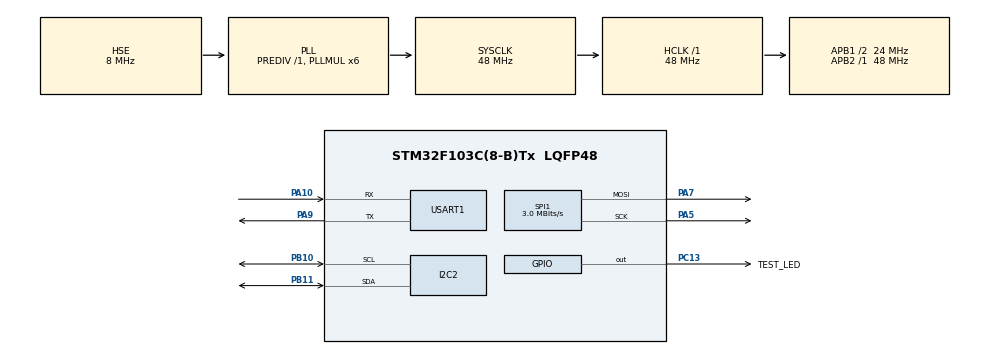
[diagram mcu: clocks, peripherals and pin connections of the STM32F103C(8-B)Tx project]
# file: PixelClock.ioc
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Dma.Request0=SPI1_TX
Dma.Request1=USART1_RX
Dma.Request2=USART1_TX
Dma.SPI1_TX.0.Direction=DMA_MEMORY_TO_PERIPH
Dma.SPI1_TX.0.Instance=DMA1_Channel3
Dma.SPI1_TX.0.MemDataAlignment=DMA_MDATAALIGN_BYTE
Dma.SPI1_TX.0.MemInc=DMA_MINC_ENABLE
Dma.SPI1_TX.0.Mode=DMA_NORMAL
Dma.SPI1_TX.0.PeriphDataAlignment=DMA_PDATAALIGN_BYTE
Dma.SPI1_TX.0.PeriphInc=DMA_PINC_DISABLE
Dma.SPI1_TX.0.Priority=DMA_PRIORITY_LOW
Dma.USART1_RX.1.Direction=DMA_PERIPH_TO_MEMORY
Dma.USART1_RX.1.Instance=DMA1_Channel5
Dma.USART1_RX.1.MemDataAlignment=DMA_MDATAALIGN_BYTE
Dma.USART1_RX.1.MemInc=DMA_MINC_ENABLE
Dma.USART1_RX.1.Mode=DMA_CIRCULAR
Dma.USART1_RX.1.PeriphDataAlignment=DMA_PDATAALIGN_BYTE
Dma.USART1_RX.1.PeriphInc=DMA_PINC_DISABLE
Dma.USART1_RX.1.Priority=DMA_PRIORITY_LOW
Dma.USART1_TX.2.Direction=DMA_MEMORY_TO_PERIPH
Dma.USART1_TX.2.Instance=DMA1_Channel4
Dma.USART1_TX.2.MemDataAlignment=DMA_MDATAALIGN_BYTE
Dma.USART1_TX.2.MemInc=DMA_MINC_ENABLE
Dma.USART1_TX.2.Mode=DMA_NORMAL
Dma.USART1_TX.2.PeriphDataAlignment=DMA_PDATAALIGN_BYTE
Dma.USART1_TX.2.PeriphInc=DMA_PINC_DISABLE
Dma.USART1_TX.2.Priority=DMA_PRIORITY_LOW
FREERTOS.INCLUDE_xEventGroupSetBitFromISR=1
FREERTOS.Tasks01=defaultTask,24,128,StartDefaultTask,Default,NULL,Dynamic,NULL,NULL;LedTask,8,128,StartLedTask,Default,NULL,Dynamic,NULL,NULL
I2C2.I2C_Mode=I2C_Standard
Mcu.Family=STM32F1
Mcu.Name=STM32F103C(8-B)Tx
Mcu.Package=LQFP48
NVIC.DMA1_Channel3_IRQn=true\:5\:0\:false\:false\:true\:true\:false\:true
NVIC.DMA1_Channel4_IRQn=true\:5\:0\:false\:false\:true\:true\:false\:true
NVIC.DMA1_Channel5_IRQn=true\:5\:0\:false\:false\:true\:true\:false\:true
NVIC.PriorityGroup=NVIC_PRIORITYGROUP_4
NVIC.RTC_IRQn=true\:5\:0\:false\:false\:true\:true\:true\:true
NVIC.TIM4_IRQn=true\:0\:0\:false\:false\:true\:false\:false\:true
NVIC.TimeBase=TIM4_IRQn
NVIC.TimeBaseIP=TIM4
NVIC.USART1_IRQn=true\:5\:0\:false\:false\:true\:true\:true\:true
PA10.Mode=Asynchronous
PA10.Signal=USART1_RX
PA13.Mode=Serial_Wire
PA13.Signal=SYS_JTMS-SWDIO
PA14.Mode=Serial_Wire
PA14.Signal=SYS_JTCK-SWCLK
PA5.Mode=TX_Only_Simplex_Unidirect_Master
PA5.Signal=SPI1_SCK
PA7.Mode=TX_Only_Simplex_Unidirect_Master
PA7.Signal=SPI1_MOSI
PA9.Mode=Asynchronous
PA9.Signal=USART1_TX
PB10.Mode=I2C
PB10.Signal=I2C2_SCL
PB11.Mode=I2C
PB11.Signal=I2C2_SDA
PC13-TAMPER-RTC.GPIO_Label=TEST_LED
PC13-TAMPER-RTC.Signal=GPIO_Output
PC14-OSC32_IN.Mode=LSE-External-Oscillator
PC14-OSC32_IN.Signal=RCC_OSC32_IN
PC15-OSC32_OUT.Mode=LSE-External-Oscillator
PC15-OSC32_OUT.Signal=RCC_OSC32_OUT
PD0-OSC_IN.Mode=HSE-External-Oscillator
PD0-OSC_IN.Signal=RCC_OSC_IN
PD1-OSC_OUT.Mode=HSE-External-Oscillator
PD1-OSC_OUT.Signal=RCC_OSC_OUT
ProjectManager.HeapSize=0x200
ProjectManager.StackSize=0x400
ProjectManager.TargetToolchain=STM32CubeIDE
RCC.AHBFreq_Value=48000000
RCC.APB1CLKDivider=RCC_HCLK_DIV2
RCC.APB1Freq_Value=24000000
RCC.APB1TimFreq_Value=48000000
RCC.APB2Freq_Value=48000000
RCC.APB2TimFreq_Value=48000000
RCC.HCLKFreq_Value=48000000
RCC.PLLMUL=RCC_PLL_MUL6
RCC.PLLSourceVirtual=RCC_PLLSOURCE_HSE
RCC.RTCClockSelection=RCC_RTCCLKSOURCE_LSE
RCC.SYSCLKFreq_VALUE=48000000
RCC.SYSCLKSource=RCC_SYSCLKSOURCE_PLLCLK
RCC.USBFreq_Value=48000000
RTC.Format=RTC_FORMAT_BIN
SPI1.BaudRatePrescaler=SPI_BAUDRATEPRESCALER_16
SPI1.CalculateBaudRate=3.0 MBits/s
SPI1.DataSize=SPI_DATASIZE_8BIT
SPI1.Direction=SPI_DIRECTION_2LINES
SPI1.Mode=SPI_MODE_MASTER
SPI1.VirtualType=VM_MASTER
USART1.VirtualMode=VM_ASYNC
VP_FREERTOS_VS_CMSIS_V2.Mode=CMSIS_V2
VP_RTC_VS_RTC_Activate.Mode=RTC_Enabled
VP_SYS_VS_tim4.Mode=TIM4
board=custom

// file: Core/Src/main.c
/* USER CODE BEGIN Header */
/**
  ******************************************************************************
  * @file           : main.c
  * @brief          : Main program body
  ******************************************************************************
  * @attention
  *
  * <h2><center>&copy; Copyright (c) 2020 STMicroelectronics.
  * All rights reserved.</center></h2>
  *
  * This software component is licensed by ST under BSD 3-Clause license,
  * the "License"; You may not use this file except in compliance with the
  * License. You may obtain a copy of the License at:
  *                        opensource.org/licenses/BSD-3-Clause
  *
  ******************************************************************************
  */
/* USER CODE END Header */

#include "main.h"
#include "cmsis_os.h"

/* USER CODE BEGIN Includes */
#include "math.h"
#include "stdlib.h"
#include "time.h"
#include "ds3231.h"
/* USER CODE END Includes */

/* USER CODE BEGIN PTD */
enum flag_frame_state {
	WAIT_FOR_FRAME_START,
	WAIT_FOR_DATA
};

typedef enum font_size {
	THREE_BY_FIVE,
	THREE_BY_SEVEN,
	FOUR_BY_SEVEN,
	FOUR_BY_EIGHT,
	FIVE_BY_SEVEN,
	FIVE_BY_EIGHT
} t_font_size;

/* USER CODE END PTD */

/* USER CODE BEGIN PD */
#define	OFFSET			1
#define	NUM_ROW			8
#define NUM_COLUMN		20

#define NUM_LEDS				((NUM_ROW * NUM_COLUMN) + OFFSET)
#define	PIXELS_DATA_SIZE		NUM_LEDS*3
#define TOTAL_PIXELS_DATA_SIZE 	PIXELS_DATA_SIZE*3 + 1 //+1 to keep mosi Low by default to simulate proper LED reset condition

#define RX_DATA_SIZE 128
#define TX_DATA_SIZE 128

/* USER CODE END PD */

/* USER CODE BEGIN PM */
#define ARRAY_LEN(x)            (sizeof(x) / sizeof((x)[0]))
/* USER CODE END PM */

I2C_HandleTypeDef hi2c2;

RTC_HandleTypeDef hrtc;

SPI_HandleTypeDef hspi1;
DMA_HandleTypeDef hdma_spi1_tx;

UART_HandleTypeDef huart1;
DMA_HandleTypeDef hdma_usart1_rx;
DMA_HandleTypeDef hdma_usart1_tx;

/* Definitions for defaultTask */
osThreadId_t defaultTaskHandle;
const osThreadAttr_t defaultTask_attributes = {
  .name = "defaultTask",
  .priority = (osPriority_t) osPriorityNormal,
  .stack_size = 128 * 4
};
/* Definitions for LedTask */
osThreadId_t LedTaskHandle;
const osThreadAttr_t LedTask_attributes = {
  .name = "LedTask",
  .priority = (osPriority_t) osPriorityLow,
  .stack_size = 128 * 4
};
/* USER CODE BEGIN PV */

static uint8_t uart_rx_data[RX_DATA_SIZE];
static uint8_t uart_tx_data[TX_DATA_SIZE];

uint8_t	leda[TOTAL_PIXELS_DATA_SIZE]; //display pixel
uint8_t	leda_foreground[TOTAL_PIXELS_DATA_SIZE]; //foreground color

volatile uint8_t r_offset_dig_0,r_offset_dig_1,r_offset_dig_2,r_offset_dig_3;

static const uint8_t encoderLookup[256*3]={	0x92,0x49,0x24,0x92,0x49,0x26,0x92,0x49,0x34,0x92,0x49,0x36,0x92,0x49,0xA4,0x92,0x49,0xA6,0x92,0x49,0xB4,0x92,0x49,0xB6,0x92,0x4D,0x24,0x92,0x4D,0x26,0x92,0x4D,0x34,0x92,0x4D,0x36,0x92,0x4D,0xA4,0x92,0x4D,0xA6,0x92,0x4D,0xB4,0x92,0x4D,0xB6,0x92,0x69,0x24,0x92,0x69,0x26,0x92,0x69,0x34,0x92,0x69,0x36,0x92,0x69,0xA4,0x92,0x69,0xA6,0x92,0x69,0xB4,0x92,0x69,0xB6,0x92,0x6D,0x24,0x92,0x6D,0x26,0x92,0x6D,0x34,0x92,0x6D,0x36,0x92,0x6D,0xA4,0x92,0x6D,0xA6,0x92,0x6D,0xB4,0x92,0x6D,0xB6,0x93,0x49,0x24,0x93,0x49,0x26,0x93,0x49,0x34,0x93,0x49,0x36,0x93,0x49,0xA4,0x93,0x49,0xA6,0x93,0x49,0xB4,0x93,0x49,0xB6,0x93,0x4D,0x24,0x93,0x4D,0x26,0x93,0x4D,0x34,0x93,0x4D,0x36,0x93,0x4D,0xA4,0x93,0x4D,0xA6,0x93,0x4D,0xB4,0x93,0x4D,0xB6,0x93,0x69,0x24,0x93,0x69,0x26,0x93,0x69,0x34,0x93,0x69,0x36,0x93,0x69,0xA4,0x93,0x69,0xA6,0x93,0x69,0xB4,0x93,0x69,0xB6,0x93,0x6D,0x24,0x93,0x6D,0x26,0x93,0x6D,0x34,0x93,0x6D,0x36,0x93,0x6D,0xA4,0x93,0x6D,0xA6,0x93,0x6D,0xB4,0x93,0x6D,0xB6,0x9A,0x49,0x24,0x9A,0x49,0x26,0x9A,0x49,0x34,0x9A,0x49,0x36,0x9A,0x49,0xA4,0x9A,0x49,0xA6,0x9A,0x49,0xB4,0x9A,0x49,0xB6,0x9A,0x4D,0x24,0x9A,0x4D,0x26,0x9A,0x4D,0x34,0x9A,0x4D,0x36,0x9A,0x4D,0xA4,0x9A,0x4D,0xA6,0x9A,0x4D,0xB4,0x9A,0x4D,0xB6,0x9A,0x69,0x24,0x9A,0x69,0x26,0x9A,0x69,0x34,0x9A,0x69,0x36,0x9A,0x69,0xA4,0x9A,0x69,\
											0xA6,0x9A,0x69,0xB4,0x9A,0x69,0xB6,0x9A,0x6D,0x24,0x9A,0x6D,0x26,0x9A,0x6D,0x34,0x9A,0x6D,0x36,0x9A,0x6D,0xA4,0x9A,0x6D,0xA6,0x9A,0x6D,0xB4,0x9A,0x6D,0xB6,0x9B,0x49,0x24,0x9B,0x49,0x26,0x9B,0x49,0x34,0x9B,0x49,0x36,0x9B,0x49,0xA4,0x9B,0x49,0xA6,0x9B,0x49,0xB4,0x9B,0x49,0xB6,0x9B,0x4D,0x24,0x9B,0x4D,0x26,0x9B,0x4D,0x34,0x9B,0x4D,0x36,0x9B,0x4D,0xA4,0x9B,0x4D,0xA6,0x9B,0x4D,0xB4,0x9B,0x4D,0xB6,0x9B,0x69,0x24,0x9B,0x69,0x26,0x9B,0x69,0x34,0x9B,0x69,0x36,0x9B,0x69,0xA4,0x9B,0x69,0xA6,0x9B,0x69,0xB4,0x9B,0x69,0xB6,0x9B,0x6D,0x24,0x9B,0x6D,0x26,0x9B,0x6D,0x34,0x9B,0x6D,0x36,0x9B,0x6D,0xA4,0x9B,0x6D,0xA6,0x9B,0x6D,0xB4,0x9B,0x6D,0xB6,0xD2,0x49,0x24,0xD2,0x49,0x26,0xD2,0x49,0x34,0xD2,0x49,0x36,0xD2,0x49,0xA4,0xD2,0x49,0xA6,0xD2,0x49,0xB4,0xD2,0x49,0xB6,0xD2,0x4D,0x24,0xD2,0x4D,0x26,0xD2,0x4D,0x34,0xD2,0x4D,0x36,0xD2,0x4D,0xA4,0xD2,0x4D,0xA6,0xD2,0x4D,0xB4,0xD2,0x4D,0xB6,0xD2,0x69,0x24,0xD2,0x69,0x26,0xD2,0x69,0x34,0xD2,0x69,0x36,0xD2,0x69,0xA4,0xD2,0x69,0xA6,0xD2,0x69,0xB4,0xD2,0x69,0xB6,0xD2,0x6D,0x24,0xD2,0x6D,0x26,0xD2,0x6D,0x34,0xD2,0x6D,0x36,0xD2,0x6D,0xA4,0xD2,0x6D,0xA6,0xD2,0x6D,0xB4,0xD2,0x6D,0xB6,0xD3,0x49,0x24,0xD3,0x49,0x26,0xD3,0x49,0x34,0xD3,0x49,0x36,0xD3,0x49,0xA4,0xD3,0x49,0xA6,0xD3,0x49,0xB4,0xD3,0x49,0xB6,0xD3,0x4D,0x24,0xD3,0x4D,0x26,0xD3,0x4D,0x34,0xD3,\
											0x4D,0x36,0xD3,0x4D,0xA4,0xD3,0x4D,0xA6,0xD3,0x4D,0xB4,0xD3,0x4D,0xB6,0xD3,0x69,0x24,0xD3,0x69,0x26,0xD3,0x69,0x34,0xD3,0x69,0x36,0xD3,0x69,0xA4,0xD3,0x69,0xA6,0xD3,0x69,0xB4,0xD3,0x69,0xB6,0xD3,0x6D,0x24,0xD3,0x6D,0x26,0xD3,0x6D,0x34,0xD3,0x6D,0x36,0xD3,0x6D,0xA4,0xD3,0x6D,0xA6,0xD3,0x6D,0xB4,0xD3,0x6D,0xB6,0xDA,0x49,0x24,0xDA,0x49,0x26,0xDA,0x49,0x34,0xDA,0x49,0x36,0xDA,0x49,0xA4,0xDA,0x49,0xA6,0xDA,0x49,0xB4,0xDA,0x49,0xB6,0xDA,0x4D,0x24,0xDA,0x4D,0x26,0xDA,0x4D,0x34,0xDA,0x4D,0x36,0xDA,0x4D,0xA4,0xDA,0x4D,0xA6,0xDA,0x4D,0xB4,0xDA,0x4D,0xB6,0xDA,0x69,0x24,0xDA,0x69,0x26,0xDA,0x69,0x34,0xDA,0x69,0x36,0xDA,0x69,0xA4,0xDA,0x69,0xA6,0xDA,0x69,0xB4,0xDA,0x69,0xB6,0xDA,0x6D,0x24,0xDA,0x6D,0x26,0xDA,0x6D,0x34,0xDA,0x6D,0x36,0xDA,0x6D,0xA4,0xDA,0x6D,0xA6,0xDA,0x6D,0xB4,0xDA,0x6D,0xB6,0xDB,0x49,0x24,0xDB,0x49,0x26,0xDB,0x49,0x34,0xDB,0x49,0x36,0xDB,0x49,0xA4,0xDB,0x49,0xA6,0xDB,0x49,0xB4,0xDB,0x49,0xB6,0xDB,0x4D,0x24,0xDB,0x4D,0x26,0xDB,0x4D,0x34,0xDB,0x4D,0x36,0xDB,0x4D,0xA4,0xDB,0x4D,0xA6,0xDB,0x4D,0xB4,0xDB,0x4D,0xB6,0xDB,0x69,0x24,0xDB,0x69,0x26,0xDB,0x69,0x34,0xDB,0x69,0x36,0xDB,0x69,0xA4,0xDB,0x69,0xA6,0xDB,0x69,0xB4,0xDB,0x69,0xB6,0xDB,0x6D,0x24,0xDB,0x6D,0x26,0xDB,0x6D,0x34,0xDB,0x6D,0x36,0xDB,0x6D,0xA4,0xDB,0x6D,0xA6,0xDB,0x6D,0xB4,0xDB,0x6D,0xB6};

const uint8_t charmap_three_by_five[][3] = {
		{
				0b00000000, //0x00
				0b00000000,
				0b00000000
		},
		{
				0b00000000, //0x01
				0b00000000,
				0b00000000
		},
		{
				0b00000000, //0x02
				0b00000000,
				0b00000000
		},
		{
				0b00000000, //0x03
				0b00000000,
				0b00000000
		},
		{
				0b00000000, //0x04
				0b00000000,
				0b00000000
		},
		{
				0b00000000, //0x05
				0b00000000,
				0b00000000
		},
		{
				0b00000000, //0x06
				0b00000000,
				0b00000000
		},
		{
				0b00000000, //0x07
				0b00000000,
				0b00000000
		},
		{
				0b00000000, //0x08
				0b00000000,
				0b00000000
		},
		{
				0b00000000, //0x09
				0b00000000,
				0b00000000
		},
		{
				0b00000000, //0x0a
				0b00000000,
				0b00000000
		},
		{
				0b00000000, //0x0b
				0b00000000,
				0b00000000
		},
		{
				0b00000000, //0x0c
				0b00000000,
				0b00000000
		},
		{
				0b00000000, //0x0d
				0b00000000,
				0b00000000
		},
		{
				0b00000000, //0x0e
				0b00000000,
				0b00000000
		},
		{
				0b00000000, //0x0f
				0b00000000,
				0b00000000
		},
		{
				0b00000000, //0x10
				0b00000000,
				0b00000000
		},
		{
				0b00000000, //0x11
				0b00000000,
				0b00000000
		},
		{
				0b00000000, //0x12
				0b00000000,
				0b00000000
		},
		{
				0b00000000, //0x13
				0b00000000,
				0b00000000
		},
		{
				0b00000000, //0x14
				0b00000000,
				0b00000000
		},
		{
				0b00000000, //0x15
				0b00000000,
				0b00000000
		},
		{
				0b00000000, //16
				0b00000000,
				0b00000000
		},
		{
				0b00000000, //17
				0b00000000,
				0b00000000
		},
		{
				0b00000000, //18
				0b00000000,
				0b00000000
		},
		{
				0b00000000, //19
				0b00000000,
				0b00000000
		},
		{
				0b00000000, //1a
				0b00000000,
				0b00000000
		},
		{
				0b00000000, //1b
				0b00000000,
				0b00000000
		},
		{
				0b00000000, //1c
				0b00000000,
				0b00000000
		},
		{
				0b00000000, //1d
				0b00000000,
				0b00000000
		},
		{
				0b00000000, //1e
				0b00000000,
				0b00000000
		},
		{
				0b00000000, //1f
				0b00000000,
				0b00000000
		},
		{
				0b00000000, //20
				0b00000000,
				0b00000000
		},
		{
				0b00000000, //21 !
				0b00000000,
				0b00000000
		},
		{
				0b00000000, //22 "
				0b00000000,
				0b00000000
		},
		{
				0b00000000, //23 #
				0b00000000,
				0b00000000
		},
		{
				0b00000000, //24 $
				0b00000000,
				0b00000000
		},
		{
				0b00000000, //25 %
				0b00000000,
				0b00000000
		},
		{
				0b00000000, //26 &
				0b00000000,
				0b00000000
		},
		{
				0b00000000, //27 '
				0b00000000,
				0b00000000
		},
		{
				0b00000000, //28 (
				0b00000000,
				0b00000000
		},
		{
				0b00000000, //29 )
				0b00000000,
				0b00000000
		},
		{
				0b00000000, //2a *
				0b00000000,
				0b00000000
		},
		{
				0b00000000, //2b +
				0b00000000,
				0b00000000
		},
		{
				0b00000000, //2c ,
				0b00000000,
				0b00000000
		},
		{
				0b00000000, //2d -
				0b00000000,
				0b00000000
		},
		{
				0b00000000, //2e .
				0b00000000,
				0b00000000
		},
		{
				0b00000000, //2f /
				0b00000000,
				0b00000000
		},
		{
				0b00111110, //30 0
				0b01000001,
				0b00111110
		},
		{
				0b01000010, //31 1
				0b01111111,
				0b01000000
		},
		{
				0b01100010, //32 2
				0b01010001,
				0b01001110
		},
		{
				0b01001001, //33 3
				0b01001001,
				0b00110110
		},
		{
				0b00001111, //34 4
				0b00001000,
				0b01111100
		},
		{
				0b00100111, //35 5
				0b01000101,
				0b00111001
		},
		{
				0b00111110, //36 6
				0b01001001,
				0b00110010
		},
		{
				0b00000001, //37 7
				0b01111001,
				0b00000111
		},
		{
				0b00110110, //38 8
				0b01001001,
				0b00110110
		},
		{
				0b00100110, //39 9
				0b01001001,
				0b00111110
		},
		{
				0b00000000, //3a :
				0b00000000,
				0b00000000
		},
		{
				0b00000000, //3b ;
				0b00000000,
				0b00000000
		},
		{
				0b00001000, //3c <
				0b00010100,
				0b00100010
		},
		{
				0b00010100, //3d =
				0b00010100,
				0b00010100
		},
		{
				0b00100010, //3e >
				0b00010100,
				0b00001000
		},
		{
				0b00000010, //3f ?
				0b01011001,
				0b00000110
		},
		{
				0b00000000, //40 @
				0b00000000,
				0b00000000
		},
		{
				0b01111110, //41 A
				0b00010001,
				0b01111110
		},
		{
				0b01111111, //42 B
				0b01001001,
				0b00110110
		},
		{
				0b00111110, //43 C
				0b01000001,
				0b00100010
		},
		{
				0b01111111, //44 D
				0b01000001,
				0b00111110
		},
		{
				0b01111111, //45 E
				0b01001001,
				0b01000001
		},
		{
				0b01111111, //46 F
				0b00001001,
				0b00000001
		},
		{
				0b00111110, //47 G
				0b01000001,
				0b00110010
		},
		{
				0b01111111, //48 H
				0b00001000,
				0b01111111
		},
		{
				0b01000001, //49 I
				0b01111111,
				0b01000001
		},
		{
				0b00100000, //4a J
				0b01000001,
				0b00111111
		},
		{
				0b01111111, //4b K
				0b00010100,
				0b01000001
		},
		{
				0b01111111, //4c L
				0b01000000,
				0b01000000
		},
		{
				0b01111111, //4d M
				0b00000110,
				0b01111111
		},
		{
				0b01111111, //4e N
				0b00110000,
				0b01111111
		},
		{
				0b00111110, //4f O
				0b01000001,
				0b00111110
		},
		{
				0b01111111, //51 P
				0b00001001,
				0b00000110
		},
		{
				0b00111110, //52 Q
				0b01000001,
				0b01111110
		},
		{
				0b01111111, // R
				0b00011001,
				0b01100110
		},
		{
				0b00100110, // S
				0b01001001,
				0b00110010
		},
		{
				0b00000001, // T
				0b01111111,
				0b00000001
		},
		{
				0b00111111, // U
				0b01000000,
				0b00111111
		},
		{
				0b00011111, // V
				0b01000000,
				0b00011111
		},
		{
				0b01111111, // W
				0b00110000,
				0b01111111
		},
		{
				0b01100011, // X
				0b00011100,
				0b01100011
		},
		{
				0b00000111, // Y
				0b01111000,
				0b00000111
		},
		{
				0b01100001, // Z
				0b01011001,
				0b01000011
		},
		{
				0b01111111, // [
				0b01000001,
				0b00000000
		},
		{
				0b00000000, //
				0b00000000,
				0b00000000
		},
		{
				0b00000000, // ]
				0b01000001,
				0b01111111
		},
		{
				0b00000110, // ^
				0b00000001,
				0b00000110
		},
		{
				0b01000000, // _
				0b01000000,
				0b01000000
		},
		{
				0b00000001, // ~
				0b00000010,
				0b00000001
		},
		{
				0b00000000, // a
				0b00000000,
				0b00000000
		},
		{
				0b00000000, // b
				0b00000000,
				0b00000000
		}
};

const uint8_t charmap_three_by_seven[][3] = {
		{
				0b00000000, //0x00
				0b00000000,
				0b00000000
		},
		{
				0b00000000, //0x01
				0b00000000,
				0b00000000
		},
		{
				0b00000000, //0x02
				0b00000000,
				0b00000000
		},
		{
				0b00000000, //0x03
				0b00000000,
				0b00000000
		},
		{
				0b00000000, //0x04
				0b00000000,
				0b00000000
		},
		{
				0b00000000, //0x05
				0b00000000,
				0b00000000
		},
		{
				0b00000000, //0x06
				0b00000000,
				0b00000000
		},
		{
				0b00000000, //0x07
				0b00000000,
				0b00000000
		},
		{
				0b00000000, //0x08
				0b00000000,
				0b00000000
		},
		{
				0b00000000, //0x09
				0b00000000,
				0b00000000
		},
		{
				0b00000000, //0x0a
				0b00000000,
				0b00000000
		},
		{
				0b00000000, //0x0b
				0b00000000,
				0b00000000
		},
		{
				0b00000000, //0x0c
				0b00000000,
				0b00000000
		},
		{
				0b00000000, //0x0d
				0b00000000,
				0b00000000
		},
		{
				0b00000000, //0x0e
				0b00000000,
				0b00000000
		},
		{
				0b00000000, //0x0f
				0b00000000,
				0b00000000
		},
		{
				0b00000000, //0x10
				0b00000000,
				0b00000000
		},
		{
				0b00000000, //0x11
				0b00000000,
				0b00000000
		},
		{
				0b00000000, //0x12
				0b00000000,
				0b00000000
		},
		{
				0b00000000, //0x13
				0b00000000,
				0b00000000
		},
		{
				0b00000000, //0x14
				0b00000000,
				0b00000000
		},
		{
				0b00000000, //0x15
				0b00000000,
				0b00000000
		},
		{
				0b00000000, //16
				0b00000000,
				0b00000000
		},
		{
				0b00000000, //17
				0b00000000,
				0b00000000
		},
		{
				0b00000000, //18
				0b00000000,
				0b00000000
		},
		{
				0b00000000, //19
				0b00000000,
				0b00000000
		},
		{
				0b00000000, //1a
				0b00000000,
				0b00000000
		},
		{
				0b00000000, //1b
				0b00000000,
				0b00000000
		},
		{
				0b00000000, //1c
				0b00000000,
				0b00000000
		},
		{
				0b00000000, //1d
				0b00000000,
				0b00000000
		},
		{
				0b00000000, //1e
				0b00000000,
				0b00000000
		},
		{
				0b00000000, //1f
				0b00000000,
				0b00000000
		},
		{
				0b00000000, //20
				0b00000000,
				0b00000000
		},
		{
				0b00000000, //21 !
				0b00000000,
				0b00000000
		},
		{
				0b00000000, //22 "
				0b00000000,
				0b00000000
		},
		{
				0b00000000, //23 #
				0b00000000,
				0b00000000
		},
		{
				0b00000000, //24 $
				0b00000000,
				0b00000000
		},
		{
				0b00000000, //25 %
				0b00000000,
				0b00000000
		},
		{
				0b00000000, //26 &
				0b00000000,
				0b00000000
		},
		{
				0b00000000, //27 '
				0b00000000,
				0b00000000
		},
		{
				0b00000000, //28 (
				0b00000000,
				0b00000000
		},
		{
				0b00000000, //29 )
				0b00000000,
				0b00000000
		},
		{
				0b00000000, //2a *
				0b00000000,
				0b00000000
		},
		{
				0b00000000, //2b +
				0b00000000,
				0b00000000
		},
		{
				0b00000000, //2c ,
				0b00000000,
				0b00000000
		},
		{
				0b00000000, //2d -
				0b00000000,
				0b00000000
		},
		{
				0b00000000, //2e .
				0b00000000,
				0b00000000
		},
		{
				0b00000000, //2f /
				0b00000000,
				0b00000000
		},
		{
				0b00111110, //30 0
				0b01000001,
				0b00111110
		},
		{
				0b01000010, //31 1
				0b01111111,
				0b01000000
		},
		{
				0b01100010, //32 2
				0b01010001,
				0b01001110
		},
		{
				0b01001001, //33 3
				0b01001001,
				0b00110110
		},
		{
				0b00001111, //34 4
				0b00001000,
				0b01111100
		},
		{
				0b00100111, //35 5
				0b01000101,
				0b00111001
		},
		{
				0b00111110, //36 6
				0b01001001,
				0b00110010
		},
		{
				0b00000001, //37 7
				0b01111001,
				0b00000111
		},
		{
				0b00110110, //38 8
				0b01001001,
				0b00110110
		},
		{
				0b00100110, //39 9
				0b01001001,
				0b00111110
		},
		{
				0b00000000, //3a :
				0b00000000,
				0b00000000
		},
		{
				0b00000000, //3b ;
				0b00000000,
				0b00000000
		},
		{
				0b00001000, //3c <
				0b00010100,
				0b00100010
		},
		{
				0b00010100, //3d =
				0b00010100,
				0b00010100
		},
		{
				0b00100010, //3e >
				0b00010100,
				0b00001000
		},
		{
				0b00000010, //3f ?
				0b01011001,
				0b00000110
		},
		{
				0b00000000, //40 @
				0b00000000,
				0b00000000
		},
		{
				0b01111110, //41 A
				0b00010001,
				0b01111110
		},
		{
				0b01111111, //42 B
				0b01001001,
				0b00110110
		},
		{
				0b00111110, //43 C
				0b01000001,
				0b00100010
		},
		{
				0b01111111, //44 D
				0b01000001,
				0b00111110
		},
		{
				0b01111111, //45 E
				0b01001001,
				0b01000001
		},
		{
				0b01111111, //46 F
				0b00001001,
				0b00000001
		},
		{
				0b00111110, //47 G
				0b01000001,
				0b00110010
		},
		{
				0b01111111, //48 H
				0b00001000,
				0b01111111
		},
		{
				0b01000001, //49 I
				0b01111111,
				0b01000001
		},
		{
				0b00100000, //4a J
				0b01000001,
				0b00111111
		},
		{
				0b01111111, //4b K
				0b00010100,
				0b01000001
		},
		{
				0b01111111, //4c L
				0b01000000,
				0b01000000
		},
		{
				0b01111111, //4d M
				0b00000110,
				0b01111111
		},
		{
				0b01111111, //4e N
				0b00110000,
				0b01111111
		},
		{
				0b00111110, //4f O
				0b01000001,
				0b00111110
		},
		{
				0b01111111, //51 P
				0b00001001,
				0b00000110
		},
		{
				0b00111110, //52 Q
				0b01000001,
				0b01111110
		},
		{
				0b01111111, // R
				0b00011001,
				0b01100110
		},
		{
				0b00100110, // S
				0b01001001,
				0b00110010
		},
		{
				0b00000001, // T
				0b01111111,
				0b00000001
		},
		{
				0b00111111, // U
				0b01000000,
				0b00111111
		},
		{
				0b00011111, // V
				0b01000000,
				0b00011111
		},
		{
				0b01111111, // W
				0b00110000,
				0b01111111
		},
		{
				0b01100011, // X
				0b00011100,
				0b01100011
		},
		{
				0b00000111, // Y
				0b01111000,
				0b00000111
		},
		{
				0b01100001, // Z
				0b01011001,
				0b01000011
		},
		{
				0b01111111, // [
				0b01000001,
				0b00000000
		},
		{
				0b00000000, //
				0b00000000,
				0b00000000
		},
		{
				0b00000000, // ]
				0b01000001,
				0b01111111
		},
		{
				0b00000110, // ^
				0b00000001,
				0b00000110
		},
		{
				0b01000000, // _
				0b01000000,
				0b01000000
		},
		{
				0b00000001, // ~
				0b00000010,
				0b00000001
		},
		{
				0b00000000, // a
				0b00000000,
				0b00000000
		},
		{
				0b00000000, // b
				0b00000000,
				0b00000000
		}
};

const uint8_t charmap_four_by_seven[][4] = {
		{
				0b00000000, //0x00
				0b00000000,
				0b00000000,
				0b00000000
		},
		{
				0b00000000, //0x01
				0b00000000,
				0b00000000,
				0b00000000
		},
		{
				0b00000000, //0x02
				0b00000000,
				0b00000000,
				0b00000000
		},
		{
				0b00000000, //0x03
				0b00000000,
				0b00000000,
				0b00000000
		},
		{
				0b00000000, //0x04
				0b00000000,
				0b00000000,
				0b00000000
		},
		{
				0b00000000, //0x05
				0b00000000,
				0b00000000,
				0b00000000
		},
		{
				0b00000000, //0x06
				0b00000000,
				0b00000000,
				0b00000000
		},
		{
				0b00000000, //0x07
				0b00000000,
				0b00000000,
				0b00000000
		},
		{
				0b00000000, //0x08
				0b00000000,
				0b00000000,
				0b00000000
		},
		{
				0b00000000, //0x09
				0b00000000,
				0b00000000,
				0b00000000
		},
		{
				0b00000000, //0x0a
				0b00000000,
				0b00000000,
				0b00000000
		},
		{
				0b00000000, //0x0b
				0b00000000,
				0b00000000,
				0b00000000
		},
		{
				0b00000000, //0x0c
				0b00000000,
				0b00000000,
				0b00000000
		},
		{
				0b00000000, //0x0d
				0b00000000,
				0b00000000,
				0b00000000
		},
		{
				0b00000000, //0x0e
				0b00000000,
				0b00000000,
				0b00000000
		},
		{
				0b00000000, //0x0f
				0b00000000,
				0b00000000
		},
		{
				0b00000000, //0x10
				0b00000000,
				0b00000000,
				0b00000000
		},
		{
				0b00000000, //0x11
				0b00000000,
				0b00000000,
				0b00000000
		},
		{
				0b00000000, //0x12
				0b00000000,
				0b00000000,
				0b00000000
		},
		{
				0b00000000, //0x13
				0b00000000,
				0b00000000,
				0b00000000
		},
		{
				0b00000000, //0x14
				0b00000000,
				0b00000000,
				0b00000000
		},
		{
				0b00000000, //0x15
				0b00000000,
				0b00000000,
				0b00000000
		},
		{
				0b00000000, //16
				0b00000000,
				0b00000000,
				0b00000000
		},
		{
				0b00000000, //17
				0b00000000,
				0b00000000,
				0b00000000
		},
		{
				0b00000000, //18
				0b00000000,
				0b00000000,
				0b00000000
		},
		{
				0b00000000, //19
				0b00000000,
				0b00000000,
				0b00000000
		},
		{
				0b00000000, //1a
				0b00000000,
				0b00000000,
				0b00000000
		},
		{
				0b00000000, //1b
				0b00000000,
				0b00000000,
				0b00000000
		},
		{
				0b00000000, //1c
				0b00000000,
				0b00000000,
				0b00000000
		},
		{
				0b00000000, //1d
				0b00000000,
				0b00000000,
				0b00000000
		},
		{
				0b00000000, //1e
				0b00000000,
				0b00000000,
				0b00000000
		},
		{
				0b00000000, //1f
				0b00000000,
				0b00000000,
				0b00000000
		},
		{
				0b00000000, //20
				0b00000000,
				0b00000000,
				0b00000000
		},
		{
				0b00000000, //21 !
				0b00000000,
				0b00000000,
				0b00000000
		},
		{
				0b00000000, //22 "
				0b00000000,
				0b00000000,
				0b00000000
		},
		{
				0b00000000, //23 #
				0b00000000,
				0b00000000,
				0b00000000
		},
		{
				0b00000000, //24 $
				0b00000000,
				0b00000000,
				0b00000000
		},
		{
				0b00000000, //25 %
				0b00000000,
				0b00000000,
				0b00000000
		},
		{
				0b00000000, //26 &
				0b00000000,
				0b00000000,
				0b00000000
		},
		{
				0b00000000, //27 '
				0b00000000,
				0b00000000,
				0b00000000
		},
		{
				0b00000000, //28 (
				0b00000000,
				0b00000000,
				0b00000000
		},
		{
				0b00000000, //29 )
				0b00000000,
				0b00000000,
				0b00000000
		},
		{
				0b00000000, //2a *
				0b00000000,
				0b00000000,
				0b00000000
		},
		{
				0b00000000, //2b +
				0b00000000,
				0b00000000,
				0b00000000
		},
		{
				0b00000000, //2c ,
				0b00000000,
				0b00000000,
				0b00000000
		},
		{
				0b00000000, //2d -
				0b00000000,
				0b00000000,
				0b00000000
		},
		{
				0b00000000, //2e .
				0b00000000,
				0b00000000,
				0b00000000
		},
		{
				0b00000000, //2f /
				0b00000000,
				0b00000000,
				0b00000000
		},
		{
				0b00111110, //0
				0b01000001,
				0b01000001,
				0b00111110
		},
		{
				0b01000010, //1
				0b01111111,
				0b01000000,
				0b00000000
		},
		{
				0b01100010, //2
				0b01010001,
				0b01001001,
				0b01000110
		},
		{
				0b01001001, //3
				0b01001001,
				0b01001001,
				0b00110110
		},
		{
				0b00011111, //4
				0b00010000,
				0b01111100,
				0b00010000
		},
		{
				0b00100111, //5
				0b01000101,
				0b01000101,
				0b00111001
		},
		{
				0b00111110, //6
				0b01001001,
				0b01001001,
				0b00110000
		},
		{
				0b01100001, //7
				0b00010001,
				0b00001001,
				0b00000111
		},
		{
				0b00110110, //8
				0b01001001,
				0b01001001,
				0b00110110
		},
		{
				0b00000110, //9
				0b01001001,
				0b01001001,
				0b00111110
		},
		{
				0b00000000, //3a :
				0b00000000,
				0b00000000,
				0b00000000
		},
		{
				0b00000000, //3b ;
				0b00000000,
				0b00000000,
				0b00000000
		},
		{
				0b00001000, //3c <
				0b00010100,
				0b00000000,
				0b00100010
		},
		{
				0b00010100, //3d =
				0b00010100,
				0b00000000,
				0b00010100
		},
		{
				0b00100010, //3e >
				0b00010100,
				0b00000000,
				0b00001000
		},
		{
				0b00000010, //3f ?
				0b01011001,
				0b00000000,
				0b00000110
		},
		{
				0b00000000, //40 @
				0b00000000,
				0b00000000,
				0b00000000
		},
		{
				0b01111110, //41 A
				0b00010001,
				0b00000000,
				0b01111110
		},
		{
				0b01111111, //42 B
				0b01001001,
				0b00000000,
				0b00110110
		},
		{
				0b00111110, //43 C
				0b01000001,
				0b00000000,
				0b00100010
		},
		{
				0b01111111, //44 D
				0b01000001,
				0b00000000,
				0b00111110
		},
		{
				0b01111111, //45 E
				0b01001001,
				0b00000000,
				0b01000001
		},
		{
				0b01111111, //46 F
				0b00001001,
				0b00000000,
				0b00000001
		},
		{
				0b00111110, //47 G
				0b01000001,
				0b00000000,
				0b00110010
		},
		{
				0b01111111, //48 H
				0b00001000,
				0b00000000,
				0b01111111
		},
		{
				0b01000001, //49 I
				0b01111111,
				0b00000000,
				0b01000001
		},
		{
				0b00100000, //4a J
				0b01000001,
				0b00000000,
				0b00111111
		},
		{
				0b01111111, //4b K
				0b00010100,
				0b00000000,
				0b01000001
		},
		{
				0b01111111, //4c L
				0b01000000,
				0b00000000,
				0b01000000
		},
		{
				0b01111111, //4d M
				0b00000110,
				0b00000000,
				0b01111111
		},
		{
				0b01111111, //4e N
				0b00110000,
				0b00000000,
				0b01111111
		},
		{
				0b00111110, //4f O
				0b01000001,
				0b00000000,
				0b00111110
		},
		{
				0b01111111, //51 P
				0b00001001,
				0b00000000,
				0b00000110
		},
		{
				0b00111110, //52 Q
				0b01000001,
				0b00000000,
				0b01111110
		},
		{
				0b01111111, // R
				0b00011001,
				0b00000000,
				0b01100110
		},
		{
				0b00100110, // S
				0b01001001,
				0b00000000,
				0b00110010
		},
		{
				0b00000001, // T
				0b01111111,
				0b00000000,
				0b00000001
		},
		{
				0b00111111, // U
				0b01000000,
				0b00000000,
				0b00111111
		},
		{
				0b00011111, // V
				0b01000000,
				0b00000000,
				0b00011111
		},
		{
				0b01111111, // W
				0b00110000,
				0b00000000,
				0b01111111
		},
		{
				0b01100011, // X
				0b00011100,
				0b00000000,
				0b01100011
		},
		{
				0b00000111, // Y
				0b01111000,
				0b00000000,
				0b00000111
		},
		{
				0b01100001, // Z
				0b01011001,
				0b00000000,
				0b01000011
		},
		{
				0b01111111, // [
				0b01000001,
				0b00000000,
				0b00000000
		},
		{
				0b00000000, //
				0b00000000,
				0b00000000,
				0b00000000
		},
		{
				0b00000000, // ]
				0b01000001,
				0b00000000,
				0b01111111
		},
		{
				0b00000110, // ^
				0b00000001,
				0b00000000,
				0b00000110
		},
		{
				0b01000000, // _
				0b01000000,
				0b01000000
		},
		{
				0b00000001, // ~
				0b00000010,
				0b00000000,
				0b00000001
		},
		{
				0b00000000, // a
				0b00000000,
				0b00000000,
				0b00000000
		},
		{
				0b00000000, // b
				0b00000000,
				0b00000000,
				0b00000000
		}

};

const uint8_t charmap_five_by_seven[][5] = {
		{
				0b00000000, //0x00
				0b00000000,
				0b00000000,
				0b00000000,
				0b00000000
		},
		{
				0b00000000, //0x01
				0b00000000,
				0b00000000,
				0b00000000,
				0b00000000
		},
		{
				0b00000000, //0x02
				0b00000000,
				0b00000000,
				0b00000000,
				0b00000000
		},
		{
				0b00000000, //0x03
				0b00000000,
				0b00000000,
				0b00000000,
				0b00000000
		},
		{
				0b00000000, //0x04
				0b00000000,
				0b00000000,
				0b00000000,
				0b00000000
		},
		{
				0b00000000, //0x05
				0b00000000,
				0b00000000,
				0b00000000,
				0b00000000
		},
		{
				0b00000000, //0x06
				0b00000000,
				0b00000000,
				0b00000000,
				0b00000000
		},
		{
				0b00000000, //0x07
				0b00000000,
				0b00000000,
				0b00000000,
				0b00000000
		},
		{
				0b00000000, //0x08
				0b00000000,
				0b00000000,
				0b00000000,
				0b00000000
		},
		{
				0b00000000, //0x09
				0b00000000,
				0b00000000,
				0b00000000,
				0b00000000
		},
		{
				0b00000000, //0x0a
				0b00000000,
				0b00000000,
				0b00000000,
				0b00000000
		},
		{
				0b00000000, //0x0b
				0b00000000,
				0b00000000,
				0b00000000,
				0b00000000
		},
		{
				0b00000000, //0x0c
				0b00000000,
				0b00000000,
				0b00000000,
				0b00000000
		},
		{
				0b00000000, //0x0d
				0b00000000,
				0b00000000,
				0b00000000,
				0b00000000
		},
		{
				0b00000000, //0x0e
				0b00000000,
				0b00000000,
				0b00000000,
				0b00000000
		},
		{
				0b00000000, //0x0f
				0b00000000,
				0b00000000,
				0b00000000,
				0b00000000
		},
		{
				0b00000000, //0x10
				0b00000000,
				0b00000000,
				0b00000000,
				0b00000000
		},
		{
				0b00000000, //0x11
				0b00000000,
				0b00000000,
				0b00000000,
				0b00000000
		},
		{
				0b00000000, //0x12
				0b00000000,
				0b00000000,
				0b00000000,
				0b00000000
		},
		{
				0b00000000, //0x13
				0b00000000,
				0b00000000,
				0b00000000,
				0b00000000
		},
		{
				0b00000000, //0x14
				0b00000000,
				0b00000000,
				0b00000000,
				0b00000000
		},
		{
				0b00000000, //0x15
				0b00000000,
				0b00000000,
				0b00000000,
				0b00000000
		},
		{
				0b00000000, //16
				0b00000000,
				0b00000000,
				0b00000000,
				0b00000000
		},
		{
				0b00000000, //17
				0b00000000,
				0b00000000,
				0b00000000,
				0b00000000
		},
		{
				0b00000000, //18
				0b00000000,
				0b00000000,
				0b00000000,
				0b00000000
		},
		{
				0b00000000, //19
				0b00000000,
				0b00000000,
				0b00000000,
				0b00000000
		},
		{
				0b00000000, //1a
				0b00000000,
				0b00000000,
				0b00000000,
				0b00000000
		},
		{
				0b00000000, //1b
				0b00000000,
				0b00000000,
				0b00000000,
				0b00000000
		},
		{
				0b00000000, //1c
				0b00000000,
				0b00000000,
				0b00000000,
				0b00000000
		},
		{
				0b00000000, //1d
				0b00000000,
				0b00000000,
				0b00000000
		},
		{
				0b00000000, //1e
				0b00000000,
				0b00000000,
				0b00000000,
				0b00000000
		},
		{
				0b00000000, //1f
				0b00000000,
				0b00000000,
				0b00000000,
				0b00000000
		},
		{
				0b00000000, //20
				0b00000000,
				0b00000000,
				0b00000000,
				0b00000000
		},
		{
				0b00000000, //21 !
				0b00000000,
				0b00000000,
				0b00000000,
				0b00000000
		},
		{
				0b00000000, //22 "
				0b00000000,
				0b00000000,
				0b00000000,
				0b00000000
		},
		{
				0b00000000, //23 #
				0b00000000,
				0b00000000,
				0b00000000
		},
		{
				0b00000000, //24 $
				0b00000000,
				0b00000000,
				0b00000000,
				0b00000000
		},
		{
				0b00000000, //25 %
				0b00000000,
				0b00000000,
				0b00000000,
				0b00000000
		},
		{
				0b00000000, //26 &
				0b00000000,
				0b00000000,
				0b00000000,
				0b00000000
		},
		{
				0b00000000, //27 '
				0b00000000,
				0b00000000,
				0b00000000,
				0b00000000
		},
		{
				0b00000000, //28 (
				0b00000000,
				0b00000000,
				0b00000000,
				0b00000000
		},
		{
				0b00000000, //29 )
				0b00000000,
				0b00000000,
				0b00000000,
				0b00000000
		},
		{
				0b00000000, //2a *
				0b00000000,
				0b00000000,
				0b00000000,
				0b00000000
		},
		{
				0b00000000, //2b +
				0b00000000,
				0b00000000,
				0b00000000,
				0b00000000
		},
		{
				0b00000000, //2c ,
				0b00000000,
				0b00000000,
				0b00000000,
				0b00000000
		},
		{
				0b00000000, //2d -
				0b00000000,
				0b00000000,
				0b00000000,
				0b00000000
		},
		{
				0b00000000, //2e .
				0b00000000,
				0b00000000,
				0b00000000,
				0b00000000
		},
		{
				0b00000000, //2f /
				0b00000000,
				0b00000000,
				0b00000000,
				0b00000000
		},
		{
				0b00111110, //0
				0b01000001,
				0b01000001,
				0b00000000,
				0b00111110
		},
		{
				0b01000010, //1
				0b01111111,
				0b01000000,
				0b00000000,
				0b00000000
		},
		{
				0b01100010, //2
				0b01010001,
				0b01001001,
				0b00000000,
				0b01000110
		},
		{
				0b01001001, //3
				0b01001001,
				0b01001001,
				0b00000000,
				0b00110110
		},
		{
				0b00011111, //4
				0b00010000,
				0b01111100,
				0b00000000,
				0b00010000
		},
		{
				0b00100111, //5
				0b01000101,
				0b01000101,
				0b00000000,
				0b00111001
		},
		{
				0b00111110, //6
				0b01001001,
				0b01001001,
				0b00000000,
				0b00110000
		},
		{
				0b01100001, //7
				0b00010001,
				0b00001001,
				0b00000000,
				0b00000111
		},
		{
				0b00110110, //8
				0b01001001,
				0b01001001,
				0b00000000,
				0b00110110
		},
		{
				0b00000110, //9
				0b01001001,
				0b01001001,
				0b00000000,
				0b00111110
		},
		{
				0b00000000, //3a :
				0b00000000,
				0b00000000,
				0b00000000,
				0b00000000
		},
		{
				0b00000000, //3b ;
				0b00000000,
				0b00000000,
				0b00000000,
				0b00000000
		},
		{
				0b00001000, //3c <
				0b00010100,
				0b00000000,
				0b00000000,
				0b00100010
		},
		{
				0b00010100, //3d =
				0b00010100,
				0b00000000,
				0b00000000,
				0b00010100
		},
		{
				0b00100010, //3e >
				0b00010100,
				0b00000000,
				0b00000000,
				0b00001000
		},
		{
				0b00000010, //3f ?
				0b01011001,
				0b00000000,
				0b00000000,
				0b00000110
		},
		{
				0b00000000, //40 @
				0b00000000,
				0b00000000,
				0b00000000,
				0b00000000
		},
		{
				0b01111110, //41 A
				0b00010001,
				0b00000000,
				0b00000000,
				0b01111110
		},
		{
				0b01111111, //42 B
				0b01001001,
				0b00000000,
				0b00000000,
				0b00110110
		},
		{
				0b00111110, //43 C
				0b01000001,
				0b00000000,
				0b00000000,
				0b00100010
		},
		{
				0b01111111, //44 D
				0b01000001,
				0b00000000,
				0b00000000,
				0b00111110
		},
		{
				0b01111111, //45 E
				0b01001001,
				0b00000000,
				0b00000000,
				0b01000001
		},
		{
				0b01111111, //46 F
				0b00001001,
				0b00000000,
				0b00000000,
				0b00000001
		},
		{
				0b00111110, //47 G
				0b01000001,
				0b00000000,
				0b00000000,
				0b00110010
		},
		{
				0b01111111, //48 H
				0b00001000,
				0b00000000,
				0b00000000,
				0b01111111
		},
		{
				0b01000001, //49 I
				0b01111111,
				0b00000000,
				0b00000000,
				0b01000001
		},
		{
				0b00100000, //4a J
				0b01000001,
				0b00000000,
				0b00000000,
				0b00111111
		},
		{
				0b01111111, //4b K
				0b00010100,
				0b00000000,
				0b00000000,
				0b01000001
		},
		{
				0b01111111, //4c L
				0b01000000,
				0b00000000,
				0b00000000,
				0b01000000
		},
		{
				0b01111111, //4d M
				0b00000110,
				0b00000000,
				0b00000000,
				0b01111111
		},
		{
				0b01111111, //4e N
				0b00110000,
				0b00000000,
				0b00000000,
				0b01111111
		},
		{
				0b00111110, //4f O
				0b01000001,
				0b00000000,
				0b00000000,
				0b00111110
		},
		{
				0b01111111, //51 P
				0b00001001,
				0b00000000,
				0b00000000,
				0b00000110
		},
		{
				0b00111110, //52 Q
				0b01000001,
				0b00000000,
				0b00000000,
				0b01111110
		},
		{
				0b01111111, // R
				0b00011001,
				0b00000000,
				0b00000000,
				0b01100110
		},
		{
				0b00100110, // S
				0b01001001,
				0b00000000,
				0b00000000,
				0b00110010
		},
		{
				0b00000001, // T
				0b01111111,
				0b00000000,
				0b00000000,
				0b00000001
		},
		{
				0b00111111, // U
				0b01000000,
				0b00000000,
				0b00000000,
				0b00111111
		},
		{
				0b00011111, // V
				0b01000000,
				0b00000000,
				0b00000000,
				0b00011111
		},
		{
				0b01111111, // W
				0b00110000,
				0b00000000,
				0b00000000,
				0b01111111
		},
		{
				0b01100011, // X
				0b00011100,
				0b00000000,
				0b00000000,
				0b01100011
		},
		{
				0b00000111, // Y
				0b01111000,
				0b00000000,
				0b00000000,
				0b00000111
		},
		{
				0b01100001, // Z
				0b01011001,
				0b00000000,
				0b00000000,
				0b01000011
		},
		{
				0b01111111, // [
				0b01000001,
				0b00000000,
				0b00000000,
				0b00000000
		},
		{
				0b00000000, //
				0b00000000,
				0b00000000,
				0b00000000,
				0b00000000
		},
		{
				0b00000000, // ]
				0b01000001,
				0b00000000,
				0b00000000,
				0b01111111
		},
		{
				0b00000110, // ^
				0b00000001,
				0b00000000,
				0b00000000,
				0b00000110
		},
		{
				0b01000000, // _
				0b01000000,
				0b00000000,
				0b00000000,
				0b01000000
		},
		{
				0b00000001, // ~
				0b00000010,
				0b00000000,
				0b00000000,
				0b00000001
		},
		{
				0b00000000, // a
				0b00000000,
				0b00000000,
				0b00000000,
				0b00000000
		},
		{
				0b00000000, // b
				0b00000000,
				0b00000000,
				0b00000000,
				0b00000000
		}

};
uint32_t current_position;
uint8_t	flag_colon_display;

RTC_TimeTypeDef cTime;

osEventFlagsId_t uart1Event;
/* USER CODE END PV */

void SystemClock_Config(void);
static void MX_GPIO_Init(void);
static void MX_DMA_Init(void);
static void MX_RTC_Init(void);
static void MX_SPI1_Init(void);
static void MX_USART1_UART_Init(void);
static void MX_I2C2_Init(void);
void StartDefaultTask(void *argument);
void StartLedTask(void *argument);

/* USER CODE BEGIN PFP */
void handle_rx(UART_HandleTypeDef *huart);
void usart_process_data(const void* data, size_t len);
void setPixel(int Pixel, uint8_t red, uint8_t green, uint8_t blue);
void setPixel_foreground(int Pixel, uint8_t red, uint8_t green, uint8_t blue);
void setAll(uint8_t red, uint8_t green, uint8_t blue);
void setAll_foreground(uint8_t red, uint8_t green, uint8_t blue);
void copyForegroundPixel(int Pixel);
void showStrip(void);
void RGBLoop(void);
void RGBLoop_foreground(void);
void FadeInOut(uint8_t red, uint8_t green, uint8_t blue);
void rainbowCycle(void);
void rainbowCycle_foreground(void);
uint8_t * Wheel(uint8_t WheelPos);
void home(void);
void putchar_m(uint8_t c, t_font_size f_size, uint8_t *getColor(uint8_t arg));
void putchar_fg(uint8_t c, t_font_size f_size);
void putchar_fg_a(uint8_t prev_c, uint8_t c, t_font_size f_size,uint8_t row_offset);
void putcolon(void);
/* USER CODE END PFP */

/* USER CODE BEGIN 0 */
void HAL_RTCEx_RTCEventCallback(RTC_HandleTypeDef *hrtc){
	if(flag_colon_display) {
		flag_colon_display = 0;
	} else {
		flag_colon_display = 1;
	}
}

void HAL_UART_RxCpltCallback (UART_HandleTypeDef *huart){

	if(huart->Instance == USART1){ // WiFi
		handle_rx(huart);
		//osEventFlagsSet(uart1Event,0x01);
	}
}

void HAL_UART_ErrorCallback(UART_HandleTypeDef *huart )
{
	__HAL_UART_CLEAR_OREFLAG(huart);
	__HAL_UART_CLEAR_NEFLAG(huart);
	__HAL_UART_CLEAR_FEFLAG(huart);

	if(huart->Instance == USART1){
		HAL_UART_Receive_DMA(huart,uart_rx_data, RX_DATA_SIZE);
	}

}

void handle_rx(UART_HandleTypeDef *huart){
	static size_t old_pos;
	size_t pos;

	/* Calculate current position in buffer */
	pos = ARRAY_LEN(uart_rx_data) - huart->hdmarx->Instance->CNDTR;
	if (pos != old_pos) {
		if (pos > old_pos) {                    /* Current position is over previous one */
			/* We are in "linear" mode */
			/* Process data directly by subtracting "pointers" */
			usart_process_data(&uart_rx_data[old_pos], pos - old_pos);
		} else {
			/* We are in "overflow" mode */
			/* First process data to the end of buffer */
			usart_process_data(&uart_rx_data[old_pos], ARRAY_LEN(uart_rx_data) - old_pos);
			/* Continue from beginning of buffer */
			usart_process_data(&uart_rx_data[0], pos);
		}
	}

	old_pos = pos;

	/* Check and manually update if we reached end of buffer */
	if(old_pos == ARRAY_LEN(uart_rx_data)){
		old_pos = 0;
	}

}

void usart_process_data(const void* data, size_t len){
	const uint8_t* d = data;
	//static size_t tx_pos;
	static uint8_t flag_frame;
	static uint16_t length;
	static uint8_t i;

	while (len--) {
		switch(flag_frame){
		case WAIT_FOR_FRAME_START:
			if(*d == '[') flag_frame = WAIT_FOR_DATA;
			break;
		case WAIT_FOR_DATA:
			break;
		}
		d++;
	}
}

// Set a LED color (not yet visible)
void setPixel(int Pixel, uint8_t red, uint8_t green, uint8_t blue) {
	uint32_t j,k;

	j = Pixel*9;

	k = green*3;//color index
	//g
	leda[j++] = encoderLookup[k];
	leda[j++] = encoderLookup[k+1];
	leda[j++] = encoderLookup[k+2];

	//r
	k = red*3;//color index
	leda[j++] = encoderLookup[k];
	leda[j++] = encoderLookup[k+1];
	leda[j++] = encoderLookup[k+2];

	//b
	k = blue*3;//color index
	leda[j++] = encoderLookup[k];
	leda[j++] = encoderLookup[k+1];
	leda[j] = encoderLookup[k+2];

}

// Set a LED color for foreground pixel used by fonts
void setPixel_foreground(int Pixel, uint8_t red, uint8_t green, uint8_t blue) {
	uint32_t j,k;

	j = Pixel*9;

	k = green*3;//color index
	//g
	leda_foreground[j++] = encoderLookup[k];
	leda_foreground[j++] = encoderLookup[k+1];
	leda_foreground[j++] = encoderLookup[k+2];

	//r
	k = red*3;//color index
	leda_foreground[j++] = encoderLookup[k];
	leda_foreground[j++] = encoderLookup[k+1];
	leda_foreground[j++] = encoderLookup[k+2];

	//b
	k = blue*3;//color index
	leda_foreground[j++] = encoderLookup[k];
	leda_foreground[j++] = encoderLookup[k+1];
	leda_foreground[j] = encoderLookup[k+2];

}

void setAll(uint8_t red, uint8_t green, uint8_t blue){
	uint32_t i,j,k;

	for(i = 0;i < NUM_LEDS;i++){
		//setPixel(i,red,green,blue);
		j=i*9;
		k = green*3;//color index
		//g
		leda[j++] = encoderLookup[k];
		leda[j++] = encoderLookup[k+1];
		leda[j++] = encoderLookup[k+2];

		//r
		k = red*3;//color index
		leda[j++] = encoderLookup[k];
		leda[j++] = encoderLookup[k+1];
		leda[j++] = encoderLookup[k+2];

		//b
		k = blue*3;//color index
		leda[j++] = encoderLookup[k];
		leda[j++] = encoderLookup[k+1];
		leda[j] = encoderLookup[k+2];
	}
}

void setAll_foreground(uint8_t red, uint8_t green, uint8_t blue){
	uint32_t i,j,k;

	for(i = 0;i < NUM_LEDS;i++){
		//setPixel(i,red,green,blue);
		j=i*9;
		k = green*3;//color index
		//g
		leda_foreground[j++] = encoderLookup[k];
		leda_foreground[j++] = encoderLookup[k+1];
		leda_foreground[j++] = encoderLookup[k+2];

		//r
		k = red*3;//color index
		leda_foreground[j++] = encoderLookup[k];
		leda_foreground[j++] = encoderLookup[k+1];
		leda_foreground[j++] = encoderLookup[k+2];

		//b
		k = blue*3;//color index
		leda_foreground[j++] = encoderLookup[k];
		leda_foreground[j++] = encoderLookup[k+1];
		leda_foreground[j] = encoderLookup[k+2];
	}
}

void copyForegroundPixel(int Pixel){
	uint32_t j;

	j = Pixel*9;

	leda[j] = leda_foreground[j]; j++;
	leda[j] = leda_foreground[j]; j++;
	leda[j] = leda_foreground[j]; j++;

	leda[j] = leda_foreground[j]; j++;
	leda[j] = leda_foreground[j]; j++;
	leda[j] = leda_foreground[j]; j++;

	leda[j] = leda_foreground[j]; j++;
	leda[j] = leda_foreground[j]; j++;
	leda[j] = leda_foreground[j];

}

void showStrip(void){
	while(HAL_DMA_GetState(&hdma_spi1_tx) != HAL_DMA_STATE_READY);
	leda[TOTAL_PIXELS_DATA_SIZE-1] = 0x00; // workaround to keep mosi low by default
	osDelay(1);
	HAL_SPI_Transmit_DMA(&hspi1, leda, TOTAL_PIXELS_DATA_SIZE);
}

void RGBLoop(void){
	static uint8_t j = 0;
	static int32_t k = 0,l = 255;

	if(j < 3){
		// Fade IN
		if(k < 256) {

			switch(j) {
			case 0:
				setAll((uint8_t)k,0,0);
				break;
			case 1:
				setAll(0,(uint8_t)k,0);
				break;
			case 2:
				setAll(0,0,(uint8_t)k);
				break;
			}
			k++;
			//showStrip();
			//osDelay(3);
		} else if (l >= 0) { // Fade OUT

			switch(j) {
			case 0: setAll((uint8_t)l,0,0); break;
			case 1: setAll(0,(uint8_t)l,0); break;
			case 2: setAll(0,0,(uint8_t)l); break;
			}
			if(--l == 0){
				k = 0;
				l = 255;
				if(++j == 3) j = 0;
			}
			//showStrip();
			//osDelay(3);
		}
	}
}

void RGBLoop_foreground(void){
	static uint8_t j = 0;
	static int32_t k = 0,l = 255;

	if(j < 3){
		// Fade IN
		if(k < 256) {

			switch(j) {
			case 0:
				setAll_foreground((uint8_t)k,0,0);
				break;
			case 1:
				setAll_foreground(0,(uint8_t)k,0);
				break;
			case 2:
				setAll_foreground(0,0,(uint8_t)k);
				break;
			}
			k++;
			//showStrip();
			//osDelay(3);
		} else if (l >= 0) { // Fade OUT

			switch(j) {
			case 0: setAll_foreground((uint8_t)l,0,0); break;
			case 1: setAll_foreground(0,(uint8_t)l,0); break;
			case 2: setAll_foreground(0,0,(uint8_t)l); break;
			}
			if(--l == 0){
				k = 0;
				l = 255;
				if(++j == 3) j = 0;
			}
			//showStrip();
			//osDelay(3);
		}
	}
}

void FadeInOut(uint8_t red, uint8_t green, uint8_t blue){
  float r, g, b;

  for(int k = 0; k < 256; k=k+1) {
    r = (k/256.0)*red;
    g = (k/256.0)*green;
    b = (k/256.0)*blue;
    setAll(r,g,b);
    showStrip();
  }

  for(int k = 255; k >= 0; k=k-2) {
    r = (k/256.0)*red;
    g = (k/256.0)*green;
    b = (k/256.0)*blue;
    setAll(r,g,b);
    showStrip();
  }
}

void rainbowCycle(void) {
	uint8_t *c;
	uint16_t i = 0, j = 0;

	if(j<256) { //cycles of all colors on wheel
		if(i< NUM_LEDS) {
			c=Wheel(((i * 256 / NUM_LEDS) + j) & 255);
			setPixel(i, *c, *(c+1), *(c+2));
			if(++i >= NUM_LEDS){

			}

		}
		if(++j >= 256) j=0;//TODO:
	}
}

void rainbowCycle_foreground(void) {
	uint8_t *c;
	static uint16_t i = 0, j = 0;

	if(j<256) { //cycles of all colors on wheel
		if(i< NUM_LEDS) {
			c=Wheel(((i * 256 / NUM_LEDS) + j) & 255);
			setPixel_foreground(i, *c, *(c+1), *(c+2));
			if(++i >= NUM_LEDS){
				i=0;
				if(++j >= 256) {
					j=0;//TODO:
				}
			}
		}
	}
}

// used by rainbowCycle and theaterChaseRainbow
uint8_t * Wheel(uint8_t WheelPos) {
	static uint8_t c[3];

	if(WheelPos < 85) {
		c[0]=WheelPos * 3;
		c[1]=255 - WheelPos * 3;
		c[2]=0;
	} else if(WheelPos < 170) {
		WheelPos -= 85;
		c[0]=255 - WheelPos * 3;
		c[1]=0;
		c[2]=WheelPos * 3;
	} else {
		WheelPos -= 170;
		c[0]=0;
		c[1]=WheelPos * 3;
		c[2]=255 - WheelPos * 3;
	}

	return c;
}

void home(void){
	current_position = 0;
}

void putchar_m(uint8_t c, t_font_size f_size, uint8_t *getColor(uint8_t arg)){
	uint16_t i,j;
	uint8_t k;
	uint8_t *color;

	if(f_size == THREE_BY_FIVE){

		for(i=0;i<7;i++){ // row loop
			j = OFFSET + current_position + (i * NUM_COLUMN);

			k = (0x1 << i);

			color = getColor((i*12) & 255 );

			if((charmap_three_by_five[c][0] & k)) setPixel(j,*color,*(color+1),*(color+2));
			if((charmap_three_by_five[c][1] & k)) setPixel(j+1,*color,*(color+1),*(color+2));
			if((charmap_three_by_five[c][2] & k)) setPixel(j+2,*color,*(color+1),*(color+2));
		}

		current_position += 4;

	} else if(f_size == THREE_BY_SEVEN){

		for(i=0;i<7;i++){ // row loop
			j = OFFSET + current_position + (i * NUM_COLUMN);

			k = (0x1 << i);

			color = getColor((i*12) & 255 );

			if((charmap_three_by_seven[c][0] & k)) setPixel(j,*color,*(color+1),*(color+2));
			if((charmap_three_by_seven[c][1] & k)) setPixel(j+1,*color,*(color+1),*(color+2));
			if((charmap_three_by_seven[c][2] & k)) setPixel(j+2,*color,*(color+1),*(color+2));
		}

		current_position += 4;

	} else if(f_size == FOUR_BY_SEVEN){

		for(i=0;i<7;i++){ // row loop
			j = OFFSET + current_position + (i * NUM_COLUMN);

			k = (0x1 << i);

			color = getColor((i*12) & 255 );

			if((charmap_four_by_seven[c][0] & k)) setPixel(j,*color,*(color+1),*(color+2));
			if((charmap_four_by_seven[c][1] & k)) setPixel(j+1,*color,*(color+1),*(color+2));
			if((charmap_four_by_seven[c][2] & k)) setPixel(j+2,*color,*(color+1),*(color+2));
			if((charmap_four_by_seven[c][3] & k)) setPixel(j+3,*color,*(color+1),*(color+2));
		}

		current_position += 5;

	} else if(f_size == FOUR_BY_EIGHT){
		for(i=0;i<7;i++){ // row loop
			j = OFFSET + current_position + (i * NUM_COLUMN);

			k = (0x1 << i);

			color = getColor((i*12) & 255 );

			if((charmap_four_by_seven[c][0] & k)) setPixel(j,*color,*(color+1),*(color+2));
			if((charmap_four_by_seven[c][1] & k)) setPixel(j+1,*color,*(color+1),*(color+2));
			if((charmap_four_by_seven[c][2] & k)) setPixel(j+2,*color,*(color+1),*(color+2));
			if((charmap_four_by_seven[c][3] & k)) setPixel(j+3,*color,*(color+1),*(color+2));
		}

		current_position += 5;

	} else if(f_size == FIVE_BY_SEVEN){
		for(i=0;i<7;i++){ // row loop
			j = OFFSET + current_position + (i * NUM_COLUMN);

			k = (0x1 << i);

			color = getColor((i*12) & 255 );

			if((charmap_five_by_seven[c][0] & k)) setPixel(j,*color,*(color+1),*(color+2));
			if((charmap_five_by_seven[c][1] & k)) setPixel(j+1,*color,*(color+1),*(color+2));
			if((charmap_five_by_seven[c][2] & k)) setPixel(j+2,*color,*(color+1),*(color+2));
			if((charmap_five_by_seven[c][3] & k)) setPixel(j+3,*color,*(color+1),*(color+2));
			if((charmap_five_by_seven[c][4] & k)) setPixel(j+4,*color,*(color+1),*(color+2));
		}

		current_position += 6;

	} else if(f_size == FIVE_BY_EIGHT){
		for(i=0;i<7;i++){ // row loop
			j = OFFSET + current_position + (i * NUM_COLUMN);

			k = (0x1 << i);

			color = getColor((i*12) & 255 );

			if((charmap_five_by_seven[c][0] & k)) setPixel(j,*color,*(color+1),*(color+2));
			if((charmap_five_by_seven[c][1] & k)) setPixel(j+1,*color,*(color+1),*(color+2));
			if((charmap_five_by_seven[c][2] & k)) setPixel(j+2,*color,*(color+1),*(color+2));
			if((charmap_five_by_seven[c][3] & k)) setPixel(j+3,*color,*(color+1),*(color+2));
			if((charmap_five_by_seven[c][4] & k)) setPixel(j+4,*color,*(color+1),*(color+2));
		}

		current_position += 6;

	}
}

void putchar_fg(uint8_t c, t_font_size f_size){
	uint32_t i,j;
	uint8_t k;

	if(f_size == THREE_BY_FIVE){

		for(i=0;i<7;i++){ // row loop
			j = OFFSET + current_position + (i * NUM_COLUMN);

			k = (0x1 << i);

			if((charmap_three_by_five[c][0] & k)) copyForegroundPixel(j);
			if((charmap_three_by_five[c][1] & k)) copyForegroundPixel(j+1);
			if((charmap_three_by_five[c][2] & k)) copyForegroundPixel(j+2);
		}

		current_position += 4;

	} else if(f_size == THREE_BY_SEVEN){

		for(i=0;i<7;i++){ // row loop
			j = OFFSET + current_position + (i * NUM_COLUMN);

			k = (0x1 << i);

			if((charmap_three_by_seven[c][0] & k)) copyForegroundPixel(j);
			if((charmap_three_by_seven[c][1] & k)) copyForegroundPixel(j+1);
			if((charmap_three_by_seven[c][2] & k)) copyForegroundPixel(j+2);
		}

		current_position += 4;

	} else if(f_size == FOUR_BY_SEVEN){

		for(i=0;i<7;i++){ // row loop
			j = OFFSET + current_position + (i * NUM_COLUMN);

			k = (0x1 << i);

			if((charmap_four_by_seven[c][0] & k)) copyForegroundPixel(j);
			if((charmap_four_by_seven[c][1] & k)) copyForegroundPixel(j+1);
			if((charmap_four_by_seven[c][2] & k)) copyForegroundPixel(j+2);
			if((charmap_four_by_seven[c][3] & k)) copyForegroundPixel(j+3);
		}

		current_position += 5;

	} else if(f_size == FOUR_BY_EIGHT){
		for(i=0;i<7;i++){ // row loop
			j = OFFSET + current_position + (i * NUM_COLUMN);

			k = (0x1 << i);

			if((charmap_four_by_seven[c][0] & k)) copyForegroundPixel(j);
			if((charmap_four_by_seven[c][1] & k)) copyForegroundPixel(j+1);
			if((charmap_four_by_seven[c][2] & k)) copyForegroundPixel(j+2);
			if((charmap_four_by_seven[c][3] & k)) copyForegroundPixel(j+3);
		}

		current_position += 5;

	} else if(f_size == FIVE_BY_SEVEN){
		for(i=0;i<7;i++){ // row loop
			j = OFFSET + current_position + (i * NUM_COLUMN);

			k = (0x1 << i);

			if((charmap_five_by_seven[c][0] & k)) copyForegroundPixel(j);
			if((charmap_five_by_seven[c][1] & k)) copyForegroundPixel(j+1);
			if((charmap_five_by_seven[c][2] & k)) copyForegroundPixel(j+2);
			if((charmap_five_by_seven[c][3] & k)) copyForegroundPixel(j+3);
			if((charmap_five_by_seven[c][4] & k)) copyForegroundPixel(j+4);
		}

		current_position += 6;

	} else if(f_size == FIVE_BY_EIGHT){
		for(i=0;i<7;i++){ // row loop
			j = OFFSET + current_position + (i * NUM_COLUMN);

			k = (0x1 << i);

			if((charmap_five_by_seven[c][0] & k)) copyForegroundPixel(j);
			if((charmap_five_by_seven[c][1] & k)) copyForegroundPixel(j+1);
			if((charmap_five_by_seven[c][2] & k)) copyForegroundPixel(j+2);
			if((charmap_five_by_seven[c][3] & k)) copyForegroundPixel(j+3);
			if((charmap_five_by_seven[c][4] & k)) copyForegroundPixel(j+4);
		}

		current_position += 6;

	}
}

void putchar_fg_a(uint8_t prev_c, uint8_t c, t_font_size f_size,uint8_t row_offset){
	uint32_t i,j;
	uint8_t k,kp,l,lp;

	if(row_offset > 7) {
		row_offset = 7;
	}

	//row_offset = 1;

	if(f_size == THREE_BY_FIVE){

		for(i=0;i<7;i++){ // row loop
			j = OFFSET + current_position + (i * NUM_COLUMN);

			k = (0x1 << i);

			if((charmap_three_by_five[c][0] & k)) copyForegroundPixel(j);
			if((charmap_three_by_five[c][1] & k)) copyForegroundPixel(j+1);
			if((charmap_three_by_five[c][2] & k)) copyForegroundPixel(j+2);
		}

		current_position += 4;

	} else if(f_size == THREE_BY_SEVEN){

		for(i=0;i<7;i++){ // row loop
			j = OFFSET + current_position + (i * NUM_COLUMN);

			k = (0x1 << i);

			if((charmap_three_by_seven[c][0] & k)) copyForegroundPixel(j);
			if((charmap_three_by_seven[c][1] & k)) copyForegroundPixel(j+1);
			if((charmap_three_by_seven[c][2] & k)) copyForegroundPixel(j+2);
		}

		current_position += 4;

	} else if(f_size == FOUR_BY_SEVEN){

		for(i=0;i<7;i++){ // row loop
			j = OFFSET + current_position + (i * NUM_COLUMN);

			k = (0x01 << i);

			l = charmap_four_by_seven[c][0] >> row_offset;
			if((l & k)) copyForegroundPixel(j);

			l = charmap_four_by_seven[c][1] >> row_offset;
			if((l & k)) copyForegroundPixel(j+1);

			l = charmap_four_by_seven[c][2] >> row_offset;
			if((l & k)) copyForegroundPixel(j+2);

			l = charmap_four_by_seven[c][3] >> row_offset;
			if((l & k)) copyForegroundPixel(j+3);

		}

		for(i=0;i<8;i++){ // row loop
			j = OFFSET + current_position + (i * NUM_COLUMN);

			k = (0x01 << i);

			l = charmap_four_by_seven[prev_c][0] << (8-row_offset);
			if((l & k)) copyForegroundPixel(j);

			l = charmap_four_by_seven[prev_c][1] << (8-row_offset);
			if((l & k)) copyForegroundPixel(j+1);

			l = charmap_four_by_seven[prev_c][2] << (8-row_offset);
			if((l & k)) copyForegroundPixel(j+2);

			l = charmap_four_by_seven[prev_c][3] << (8-row_offset);
			if((l & k)) copyForegroundPixel(j+3);

		}

		current_position += 5;

	} else if(f_size == FOUR_BY_EIGHT){
		for(i=0;i<7;i++){ // row loop
			j = OFFSET + current_position + (i * NUM_COLUMN);

			k = (0x1 << i);

			if((charmap_four_by_seven[c][0] & k)) copyForegroundPixel(j);
			if((charmap_four_by_seven[c][1] & k)) copyForegroundPixel(j+1);
			if((charmap_four_by_seven[c][2] & k)) copyForegroundPixel(j+2);
			if((charmap_four_by_seven[c][3] & k)) copyForegroundPixel(j+3);
		}

		current_position += 5;

	} else if(f_size == FIVE_BY_SEVEN){
		for(i=0;i<7;i++){ // row loop
			j = OFFSET + current_position + (i * NUM_COLUMN);

			k = (0x1 << i);

			if((charmap_five_by_seven[c][0] & k)) copyForegroundPixel(j);
			if((charmap_five_by_seven[c][1] & k)) copyForegroundPixel(j+1);
			if((charmap_five_by_seven[c][2] & k)) copyForegroundPixel(j+2);
			if((charmap_five_by_seven[c][3] & k)) copyForegroundPixel(j+3);
			if((charmap_five_by_seven[c][4] & k)) copyForegroundPixel(j+4);
		}

		current_position += 6;

	} else if(f_size == FIVE_BY_EIGHT){
		for(i=0;i<7;i++){ // row loop
			j = OFFSET + current_position + (i * NUM_COLUMN);

			k = (0x1 << i);

			if((charmap_five_by_seven[c][0] & k)) copyForegroundPixel(j);
			if((charmap_five_by_seven[c][1] & k)) copyForegroundPixel(j+1);
			if((charmap_five_by_seven[c][2] & k)) copyForegroundPixel(j+2);
			if((charmap_five_by_seven[c][3] & k)) copyForegroundPixel(j+3);
			if((charmap_five_by_seven[c][4] & k)) copyForegroundPixel(j+4);
		}

		current_position += 6;

	}
}

void putcolon(void){
	uint16_t i,j;

	if(flag_colon_display){
		for(i=0;i<7;i++){ // row loop
			j = OFFSET + current_position + (i * NUM_COLUMN);

			//if(i == 1) setPixel(j,0xA0,0x10,0x10);
			if(i == 2) setPixel(j,0xA0,0x10,0x10);
			//if(i == 4) setPixel(j,0xA0,0x10,0x10);
			//if(i == 5) setPixel(j,0xA0,0x10,0x10);
			//if(i == 1) setPixel(j+1,0xA0,0x10,0x10);
			//if(i == 2) setPixel(j+1,0xA0,0x10,0x10);
			if(i == 4) setPixel(j,0xA0,0x10,0x10);
			//if(i == 5) setPixel(j+1,0xA0,0x10,0x10);
		}
	}

	current_position += 2;
}
/* USER CODE END 0 */

int main(void)
{

  /* MCU Configuration--------------------------------------------------------*/

  /* Reset of all peripherals, Initializes the Flash interface and the Systick. */
  HAL_Init();

  /* Configure the system clock */
  SystemClock_Config();

  /* Initialize all configured peripherals */
  MX_GPIO_Init();
  MX_DMA_Init();
  MX_RTC_Init();
  MX_SPI1_Init();
  MX_USART1_UART_Init();
  MX_I2C2_Init();
  /* USER CODE BEGIN 2 */
  __HAL_UART_ENABLE_IT(&huart1,UART_IT_IDLE); // enable UART IDLE interrupt
    HAL_UART_Receive_DMA(&huart1,uart_rx_data, RX_DATA_SIZE);

  /* USER CODE END 2 */

  /* Init scheduler */
  osKernelInitialize();

  /* USER CODE BEGIN RTOS_SEMAPHORES */
  /* add semaphores, ... */
  uart1Event = osEventFlagsNew(NULL);
  /* USER CODE END RTOS_SEMAPHORES */

  /* Create the thread(s) */
  /* creation of defaultTask */
  defaultTaskHandle = osThreadNew(StartDefaultTask, NULL, &defaultTask_attributes);

  /* creation of LedTask */
  LedTaskHandle = osThreadNew(StartLedTask, NULL, &LedTask_attributes);

  /* Start scheduler */
  osKernelStart();

  /* We should never get here as control is now taken by the scheduler */
  /* Infinite loop */
  while (1)
  {

  }
}

void SystemClock_Config(void)
{
  RCC_OscInitTypeDef RCC_OscInitStruct = {0};
  RCC_ClkInitTypeDef RCC_ClkInitStruct = {0};
  RCC_PeriphCLKInitTypeDef PeriphClkInit = {0};

  /** Initializes the CPU, AHB and APB busses clocks
  */
  RCC_OscInitStruct.OscillatorType = RCC_OSCILLATORTYPE_HSE|RCC_OSCILLATORTYPE_LSE;
  RCC_OscInitStruct.HSEState = RCC_HSE_ON;
  RCC_OscInitStruct.HSEPredivValue = RCC_HSE_PREDIV_DIV1;
  RCC_OscInitStruct.LSEState = RCC_LSE_ON;
  RCC_OscInitStruct.HSIState = RCC_HSI_ON;
  RCC_OscInitStruct.PLL.PLLState = RCC_PLL_ON;
  RCC_OscInitStruct.PLL.PLLSource = RCC_PLLSOURCE_HSE;
  RCC_OscInitStruct.PLL.PLLMUL = RCC_PLL_MUL6;
  if (HAL_RCC_OscConfig(&RCC_OscInitStruct) != HAL_OK)
  {
    Error_Handler();
  }
  /** Initializes the CPU, AHB and APB busses clocks
  */
  RCC_ClkInitStruct.ClockType = RCC_CLOCKTYPE_HCLK|RCC_CLOCKTYPE_SYSCLK
                              |RCC_CLOCKTYPE_PCLK1|RCC_CLOCKTYPE_PCLK2;
  RCC_ClkInitStruct.SYSCLKSource = RCC_SYSCLKSOURCE_PLLCLK;
  RCC_ClkInitStruct.AHBCLKDivider = RCC_SYSCLK_DIV1;
  RCC_ClkInitStruct.APB1CLKDivider = RCC_HCLK_DIV2;
  RCC_ClkInitStruct.APB2CLKDivider = RCC_HCLK_DIV1;

  if (HAL_RCC_ClockConfig(&RCC_ClkInitStruct, FLASH_LATENCY_1) != HAL_OK)
  {
    Error_Handler();
  }
  PeriphClkInit.PeriphClockSelection = RCC_PERIPHCLK_RTC;
  PeriphClkInit.RTCClockSelection = RCC_RTCCLKSOURCE_LSE;
  if (HAL_RCCEx_PeriphCLKConfig(&PeriphClkInit) != HAL_OK)
  {
    Error_Handler();
  }
}

static void MX_I2C2_Init(void)
{

  hi2c2.Instance = I2C2;
  hi2c2.Init.ClockSpeed = 100000;
  hi2c2.Init.DutyCycle = I2C_DUTYCYCLE_2;
  hi2c2.Init.OwnAddress1 = 0;
  hi2c2.Init.AddressingMode = I2C_ADDRESSINGMODE_7BIT;
  hi2c2.Init.DualAddressMode = I2C_DUALADDRESS_DISABLE;
  hi2c2.Init.OwnAddress2 = 0;
  hi2c2.Init.GeneralCallMode = I2C_GENERALCALL_DISABLE;
  hi2c2.Init.NoStretchMode = I2C_NOSTRETCH_DISABLE;
  if (HAL_I2C_Init(&hi2c2) != HAL_OK)
  {
    Error_Handler();
  }

}

static void MX_RTC_Init(void)
{

  /** Initialize RTC Only
  */
  hrtc.Instance = RTC;
  hrtc.Init.AsynchPrediv = RTC_AUTO_1_SECOND;
  hrtc.Init.OutPut = RTC_OUTPUTSOURCE_ALARM;
  if (HAL_RTC_Init(&hrtc) != HAL_OK)
  {
    Error_Handler();
  }
  /* USER CODE BEGIN RTC_Init 2 */
  HAL_RTCEx_SetSecond_IT(&hrtc); // second interrupt
  /* USER CODE END RTC_Init 2 */

}

static void MX_SPI1_Init(void)
{

  /* SPI1 parameter configuration*/
  hspi1.Instance = SPI1;
  hspi1.Init.Mode = SPI_MODE_MASTER;
  hspi1.Init.Direction = SPI_DIRECTION_2LINES;
  hspi1.Init.DataSize = SPI_DATASIZE_8BIT;
  hspi1.Init.CLKPolarity = SPI_POLARITY_LOW;
  hspi1.Init.CLKPhase = SPI_PHASE_1EDGE;
  hspi1.Init.NSS = SPI_NSS_SOFT;
  hspi1.Init.BaudRatePrescaler = SPI_BAUDRATEPRESCALER_16;
  hspi1.Init.FirstBit = SPI_FIRSTBIT_MSB;
  hspi1.Init.TIMode = SPI_TIMODE_DISABLE;
  hspi1.Init.CRCCalculation = SPI_CRCCALCULATION_DISABLE;
  hspi1.Init.CRCPolynomial = 10;
  if (HAL_SPI_Init(&hspi1) != HAL_OK)
  {
    Error_Handler();
  }

}

static void MX_USART1_UART_Init(void)
{

  huart1.Instance = USART1;
  huart1.Init.BaudRate = 115200;
  huart1.Init.WordLength = UART_WORDLENGTH_8B;
  huart1.Init.StopBits = UART_STOPBITS_1;
  huart1.Init.Parity = UART_PARITY_NONE;
  huart1.Init.Mode = UART_MODE_TX_RX;
  huart1.Init.HwFlowCtl = UART_HWCONTROL_NONE;
  huart1.Init.OverSampling = UART_OVERSAMPLING_16;
  if (HAL_UART_Init(&huart1) != HAL_OK)
  {
    Error_Handler();
  }

}

static void MX_DMA_Init(void)
{

  /* DMA controller clock enable */
  __HAL_RCC_DMA1_CLK_ENABLE();

  /* DMA interrupt init */
  /* DMA1_Channel3_IRQn interrupt configuration */
  HAL_NVIC_SetPriority(DMA1_Channel3_IRQn, 5, 0);
  HAL_NVIC_EnableIRQ(DMA1_Channel3_IRQn);
  /* DMA1_Channel4_IRQn interrupt configuration */
  HAL_NVIC_SetPriority(DMA1_Channel4_IRQn, 5, 0);
  HAL_NVIC_EnableIRQ(DMA1_Channel4_IRQn);
  /* DMA1_Channel5_IRQn interrupt configuration */
  HAL_NVIC_SetPriority(DMA1_Channel5_IRQn, 5, 0);
  HAL_NVIC_EnableIRQ(DMA1_Channel5_IRQn);

}

static void MX_GPIO_Init(void)
{
  GPIO_InitTypeDef GPIO_InitStruct = {0};

  /* GPIO Ports Clock Enable */
  __HAL_RCC_GPIOC_CLK_ENABLE();
  __HAL_RCC_GPIOD_CLK_ENABLE();
  __HAL_RCC_GPIOA_CLK_ENABLE();
  __HAL_RCC_GPIOB_CLK_ENABLE();

  /*Configure GPIO pin Output Level */
  HAL_GPIO_WritePin(TEST_LED_GPIO_Port, TEST_LED_Pin, GPIO_PIN_RESET);

  /*Configure GPIO pin : TEST_LED_Pin */
  GPIO_InitStruct.Pin = TEST_LED_Pin;
  GPIO_InitStruct.Mode = GPIO_MODE_OUTPUT_PP;
  GPIO_InitStruct.Pull = GPIO_NOPULL;
  GPIO_InitStruct.Speed = GPIO_SPEED_FREQ_LOW;
  HAL_GPIO_Init(TEST_LED_GPIO_Port, &GPIO_InitStruct);

}

void StartDefaultTask(void *argument)
{
  /* USER CODE BEGIN 5 */

  /* Infinite loop */
  for(;;)
  {
    //osDelay(1);
	  //osEventFlagsWait(uart1Event,0x01,osFlagsWaitAny,osWaitForever);
	  //handle_rx(&huart1);
	  osDelay(90);
	  if(r_offset_dig_0) r_offset_dig_0--;
	  if(r_offset_dig_1) r_offset_dig_1--;
	  if(r_offset_dig_2) r_offset_dig_2--;
	  if(r_offset_dig_3) r_offset_dig_3--;

  }
  /* USER CODE END 5 */
}

void StartLedTask(void *argument)
{
  /* USER CODE BEGIN StartLedTask */
	uint8_t temp_num,temp_num_prev_0,temp_num_prev_1,temp_num_prev_2,temp_num_prev_3,prev_dig_0, prev_dig_1,prev_dig_2,prev_dig_3;
  /* Infinite loop */
  for(;;)
  {
	  osDelay(5); //5minimum
	  HAL_RTC_GetTime(&hrtc, &cTime, RTC_FORMAT_BCD);

	  setAll(0x00,0x00,0x00);
	  //RGBLoop_foreground();
	  rainbowCycle_foreground();
	  home();

	  //temp_num = 0;
	  temp_num = '0' + (0x0f & (cTime.Hours >> 4));
	  //putchar_fg('1',THREE_BY_SEVEN);

	  if(prev_dig_3 != temp_num){
		  r_offset_dig_3 = 7;
		  temp_num_prev_3 = prev_dig_3;
		  prev_dig_3 = temp_num;
	  }

	  if(temp_num == '0'){
		  //print space in case of 0
		  temp_num = ' ';
		  putchar_fg_a(temp_num_prev_3,temp_num,THREE_BY_SEVEN,r_offset_dig_3);
	  } else {
		  putchar_fg_a(temp_num_prev_3,temp_num,THREE_BY_SEVEN,r_offset_dig_3);
	  }

	  temp_num = '0' + (0x0f & cTime.Hours);

	  if(prev_dig_2 != temp_num){
		  r_offset_dig_2 = 7;
		  temp_num_prev_2 = prev_dig_2;
		  prev_dig_2 = temp_num;
	  }

	  putchar_fg_a(temp_num_prev_2,temp_num,FOUR_BY_SEVEN,r_offset_dig_2);

	  putcolon(); //colon

	  temp_num = '0' + (0x0f & (cTime.Seconds >> 4));

	  if(prev_dig_1 != temp_num){
		  r_offset_dig_1 = 7;
		  temp_num_prev_1 = prev_dig_1;
		  prev_dig_1 = temp_num;

	  }

	  putchar_fg_a(temp_num_prev_1,temp_num,FOUR_BY_SEVEN,r_offset_dig_1);

	  temp_num = '0' + (0x0f & cTime.Seconds); // convert to ascii num

	  if(prev_dig_0 != temp_num){
		  r_offset_dig_0 = 7;
		  temp_num_prev_0 = prev_dig_0;
		  prev_dig_0 = temp_num;

	  }

	  putchar_fg_a(temp_num_prev_0,temp_num,FOUR_BY_SEVEN,r_offset_dig_0);

/*
	  putchar_m('2',THREE_BY_FIVE,Wheel);
	  putchar_m('1',THREE_BY_FIVE,Wheel);
	  putchar_m('A',THREE_BY_FIVE,Wheel);
	  putchar_m('U',THREE_BY_FIVE,Wheel);
	  putchar_m('G',THREE_BY_FIVE,Wheel);
*/
	  showStrip();

  }
  /* USER CODE END StartLedTask */
}

 /**
  * @brief  Period elapsed callback in non blocking mode
  * @note   This function is called  when TIM4 interrupt took place, inside
  * HAL_TIM_IRQHandler(). It makes a direct call to HAL_IncTick() to increment
  * a global variable "uwTick" used as application time base.
  * @param  htim : TIM handle
  * @retval None
  */
void HAL_TIM_PeriodElapsedCallback(TIM_HandleTypeDef *htim)
{
  if (htim->Instance == TIM4) {
    HAL_IncTick();
  }
}

void Error_Handler(void)
{
}

/************************ (C) COPYRIGHT STMicroelectronics *****END OF FILE****/
